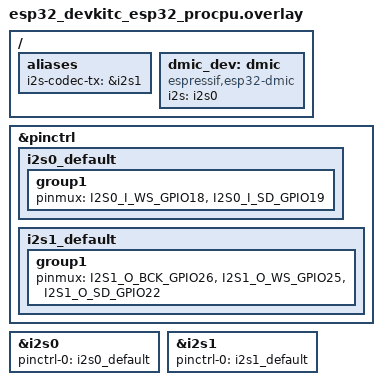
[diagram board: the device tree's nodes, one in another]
/*
 * Copyright The Zephyr Project Contributors
 *
 * SPDX-License-Identifier: Apache-2.0
 *
 * ESP32 DevKitC, and the pin-compatible DOIT ESP32 DevKit V1: a PDM MEMS
 * microphone captured through I2S0 in PDM mode by the ESP32 DMIC adapter,
 * then gain, then a MAX98357A I2S amplifier on I2S1.
 *
 * The amplifier has no control interface, so no codec node is declared and
 * the I2S sink runs without one.
 *
 * Wiring:
 *   mic  CLK -> GPIO18, DATA -> GPIO19, SEL -> GND, VDD -> 3V3, GND -> GND
 *   amp  BCLK -> GPIO26, LRC -> GPIO25, DIN -> GPIO22, VIN -> VIN (5V),
 *        GND -> GND
 *
 * These are the pins the bring-up hardware is already wired to.
 */

#include <zephyr/dt-bindings/pinctrl/esp32-pinctrl.h>

/ {
	aliases {
		i2s-codec-tx = &i2s1;
	};

	dmic_dev: dmic {
		compatible = "espressif,esp32-dmic";
		i2s = <&i2s0>;
		status = "okay";
	};
};

&pinctrl {
	/* PDM RX: the clock leaves on the WS line and data arrives on SD. */
	i2s0_default: i2s0_default {
		group1 {
			pinmux = <I2S0_I_WS_GPIO18>,
				 <I2S0_I_SD_GPIO19>;
		};
	};

	/* TX to the MAX98357A amplifier. */
	i2s1_default: i2s1_default {
		group1 {
			pinmux = <I2S1_O_BCK_GPIO26>,
				 <I2S1_O_WS_GPIO25>,
				 <I2S1_O_SD_GPIO22>;
		};
	};
};

&i2s0 {
	status = "okay";
	pinctrl-0 = <&i2s0_default>;
	pinctrl-names = "default";
};

&i2s1 {
	status = "okay";
	pinctrl-0 = <&i2s1_default>;
	pinctrl-names = "default";
};
